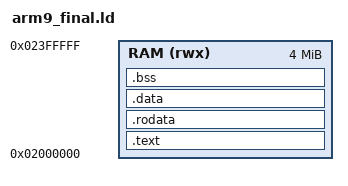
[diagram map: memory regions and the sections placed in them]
MEMORY {
    RAM (rwx) : ORIGIN = 0x02000000, LENGTH = 0x400000
}

SECTIONS {
    .text : {
        *(.text)
        *(.text.*)
    } > RAM

    .rodata : {
        *(.rodata)
        *(.rodata.*)
    } > RAM

    .data : {
        *(.data)
        *(.data.*)
    } > RAM

    .bss : {
        *(.bss)
        *(.bss.*)
        *(COMMON)
    } > RAM
}
